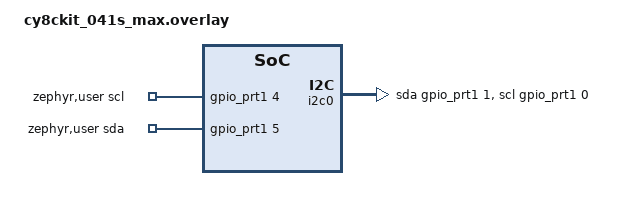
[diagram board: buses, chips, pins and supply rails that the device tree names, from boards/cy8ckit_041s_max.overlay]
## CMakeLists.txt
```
# SPDX-FileCopyrightText: Copyright (c) 2026 Infineon Technologies AG,
# SPDX-FileCopyrightText: or an affiliate of Infineon Technologies AG. All rights reserved.
#
# SPDX-License-Identifier: Apache-2.0

cmake_minimum_required(VERSION 3.28.0)

find_package(Zephyr REQUIRED HINTS $ENV{ZEPHYR_BASE})
project(i2c_fault_injection)

target_sources(app PRIVATE
  src/bus_force.c
  src/i2c_timing.c
  src/main.c
  src/test_addr.c
  src/test_api_misuse.c
  src/test_recovery.c
)
```

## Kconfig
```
# SPDX-FileCopyrightText: Copyright (c) 2026 Infineon Technologies AG,
# SPDX-FileCopyrightText: or an affiliate of Infineon Technologies AG. All rights reserved.
#
# SPDX-License-Identifier: Apache-2.0

mainmenu "I2C fault injection test"

config I2C_FAULT_TEST_ABSENT_ADDR
	hex "7-bit address that nothing on the bus answers"
	default 0x01
	range 0x01 0x77
	help
	  Address that the address-phase tests send to.  The default, 0x01,
	  is the CBUS address.  The I2C-bus specification does not allow
	  I2C-bus compatible devices to respond to it, though a system may
	  assign it to a target when CBUS is not used (UM10204 Rev. 7.0,
	  Table 4 and section 3.1.12).

	  The suite checks with one zero-length write that the address does
	  not answer before using it.  If it answers, every test skips and
	  the log names the address.  Set another address where a device on
	  the bus uses 0x01.

	  This is not a devicetree property, because devicetree describes
	  what is present on a bus and this is an address where nothing is.

config I2C_FAULT_TEST_PRESENT_ADDR
	hex "7-bit address used for the known-good transfers"
	default 0x00
	range 0x00 0x77
	help
	  Address that the suite sends to when it needs to show that the bus
	  still works.  The default, 0x00, means the first enabled devicetree
	  child of the controller under test that answers a zero-length
	  write.  Set a value where the device that answers is not in
	  devicetree.

	  Only the zero-length write is sent to this address, so the device
	  there is not written to.  If nothing answers, the tests that need a
	  known-good address skip.

config I2C_FAULT_TEST_ABSENT_ADDR_10BIT
	hex "10-bit address that nothing on the bus answers"
	default 0x2AA
	range 0x000 0x3FF
	help
	  10-bit address used by the 10-bit addressing test.  The test checks
	  with one zero-length 10-bit write that the address does not answer
	  before sending data, and skips if it does.  Set another address
	  where a device on the bus uses it.

config I2C_FAULT_TEST_BUS_FAULT_WIRED
	bool "The line-forcing GPIOs are wired to the bus"
	help
	  Declares that the GPIOs named by sda-gpios and scl-gpios under the
	  zephyr,user node are wired to the SDA and SCL nets of the controller
	  under test.  The twister scenario with the i2c_bus_fault fixture
	  sets it.

	  Devicetree names the pins but cannot say that a jumper is fitted.
	  Holding lines through pins that are not wired produces failures
	  that look like driver defects, so without this option the tests
	  that hold a line skip.  With it, the build fails unless both
	  properties are present, and setup fails unless both GPIOs are
	  ready.

config I2C_FAULT_TEST_RELAXED_ERRNO
	bool "Accept any negative errno from a failed transfer or recovery"
	help
	  The I2C API documents -EIO for a failed transfer and -ETIMEDOUT for
	  one that reached the transfer timeout, and -EBUSY for a bus that is
	  not clear after a recovery attempt, so by default this suite
	  accepts only those.  Enable this to accept any negative value
	  instead, which is useful when bringing up a driver that is not yet
	  conformant.  In both modes each test logs the value the driver
	  returned.

config I2C_FAULT_TEST_UNSAFE_API_MISUSE
	bool "Run the NULL-buffer condition without userspace"
	help
	  Runs test_misuse_null_buffer, which passes a NULL buffer with a
	  non-zero length, in a build without CONFIG_USERSPACE.  Without
	  userspace, nothing validates the buffer before the driver receives
	  it.  The driver may dereference the NULL pointer or pass it to a DMA
	  engine, and either can fault the CPU and end the run.  Off by
	  default for that reason.

config I2C_FAULT_TEST_TIMEOUT_MS
	int "Time in milliseconds the test waits for a faulted transfer"
	default 2000
	range 100 30000
	help
	  The test wait limit: how long the test thread waits for a faulted
	  transfer, which runs on a worker thread.  A transfer still running
	  at the limit fails the condition where the driver has a transfer
	  timeout shorter than this limit, and skips it elsewhere.  Without
	  the limit, a driver that never returns would show up only as a
	  twister timeout, which looks the same as a build or flash problem.

config I2C_FAULT_TEST_WORKER_STACK_SIZE
	int "Stack size in bytes for the faulted-transfer worker thread"
	default 2048
	range 512 8192
	help
	  Stack for the thread that faulted transfers run on.  It calls
	  nothing deeper than the I2C driver.

config I2C_FAULT_TEST_PAYLOAD_LEN
	int "Bytes transferred by the multi-byte conditions"
	default 8
	range 4 64
	help
	  Length of the data in the multi-byte transfers: the write, read and
	  write-read to the absent address, the read in the alternating-NACK
	  test, and the NULL-buffer write.  A refused transfer then leaves the
	  driver more than one queued byte to discard.

config I2C_FAULT_TEST_REPEAT_COUNT
	int "Attempts made by the repeated-fault conditions"
	default 5
	range 2 100
	help
	  Number of times a fault is repeated when checking that a driver
	  does not latch state from the first failure, and the number of
	  consecutive recovery calls in the repeated-recovery test.

config I2C_FAULT_TEST_HOLD_MS
	int "Milliseconds a line is held low before a recovery"
	default 20
	range 1 1000
	help
	  How long the recovery-after-release test holds SDA low through a
	  forcing GPIO before releasing it and calling i2c_recover_bus().
	  The bus is open drain, so the hold needs no timing precision.

source "Kconfig.zephyr"
```

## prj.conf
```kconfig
# SPDX-FileCopyrightText: Copyright (c) 2026 Infineon Technologies AG,
# SPDX-FileCopyrightText: or an affiliate of Infineon Technologies AG. All rights reserved.
#
# SPDX-License-Identifier: Apache-2.0

CONFIG_ZTEST=y
CONFIG_ZTEST_FATAL_HOOK=y
CONFIG_I2C=y
CONFIG_I2C_TARGET=y
CONFIG_LOG=y
CONFIG_I2C_LOG_LEVEL_WRN=y
```

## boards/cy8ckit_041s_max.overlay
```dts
/*
 * SPDX-FileCopyrightText: Copyright (c) 2026 Infineon Technologies AG,
 * SPDX-FileCopyrightText: or an affiliate of Infineon Technologies AG. All rights reserved.
 *
 * SPDX-License-Identifier: Apache-2.0
 */

/*
 * CY8CKIT-041S-MAX for the I2C fault injection suite.
 *
 * Controller under test: SCB0 on P1[0] SCL and P1[1] SDA, the Arduino I2C
 * pins.  Built with SHIELD=cy15framkit_001 and the shield fitted, its
 * FM24W256 is the known-good device.
 *
 * i2c_bus_fault fixture (kit guide 002-32436 Rev. *D, Table 1):
 *   - J2.6 (P1[4]) to J3.10 (SCL)
 *   - J2.8 (P1[5]) to J3.9 (SDA)
 */

#include <zephyr/dt-bindings/gpio/gpio.h>

/ {
	aliases {
		i2c-dut = &i2c0;
	};

	zephyr,user {
		scl-gpios = <&gpio_prt1 4 GPIO_ACTIVE_HIGH>;
		sda-gpios = <&gpio_prt1 5 GPIO_ACTIVE_HIGH>;
	};
};

/* Enables CONFIG_I2C_INFINEON_BUS_RECOVERY for the recovery tests. */
&i2c0 {
	scl-gpios = <&gpio_prt1 0 GPIO_OPEN_DRAIN>;
	sda-gpios = <&gpio_prt1 1 GPIO_OPEN_DRAIN>;
};
```

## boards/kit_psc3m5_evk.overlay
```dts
/*
 * SPDX-FileCopyrightText: Copyright (c) 2026 Infineon Technologies AG,
 * SPDX-FileCopyrightText: or an affiliate of Infineon Technologies AG. All rights reserved.
 *
 * SPDX-License-Identifier: Apache-2.0
 */

/*
 * KIT_PSC3M5_EVK for the I2C fault injection suite.  The controller under test
 * is SCB0 (i2c0) on P9[0] SCL and P9[2] SDA, at J3.10 and J3.9 (kit user
 * guide 002-39385 Rev. *B, Table 3).  The kit pulls both lines up to VTARG_REF
 * through 4.7 kOhm (R50, R51), so the bus needs no shield for its pull-ups.
 *
 * i2c_bus_fault fixture:
 *   - J5.25 (P9[1]) to J5.21 (SCL)
 *   - J5.11 (P9[4]) to J5.23 (SDA)
 *
 * P9[4] is also routed to the Shield2Go headers (J6.5, J18.5), so fit no
 * Shield2Go board while it is wired.
 */

#include <zephyr/dt-bindings/gpio/gpio.h>

/ {
	aliases {
		i2c-dut = &i2c0;
	};

	zephyr,user {
		scl-gpios = <&gpio_prt9 1 GPIO_ACTIVE_HIGH>;
		sda-gpios = <&gpio_prt9 4 GPIO_ACTIVE_HIGH>;
	};
};

/* Enables CONFIG_I2C_INFINEON_BUS_RECOVERY for the recovery tests. */
&i2c0 {
	scl-gpios = <&gpio_prt9 0 GPIO_OPEN_DRAIN>;
	sda-gpios = <&gpio_prt9 2 GPIO_OPEN_DRAIN>;
};
```

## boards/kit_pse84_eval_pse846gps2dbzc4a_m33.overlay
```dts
/*
 * SPDX-FileCopyrightText: Copyright (c) 2026 Infineon Technologies AG,
 * SPDX-FileCopyrightText: or an affiliate of Infineon Technologies AG. All rights reserved.
 *
 * SPDX-License-Identifier: Apache-2.0
 */

/*
 * KIT_PSE84_EVAL for the I2C fault injection suite (pins from kit user guide
 * 002-39007 Rev. *B, Table 2).
 *
 * Controller under test: i2c0 on P8[0] SCL and P8[1] SDA.
 *
 * i2c_bus_fault fixture, either of:
 *   - J3.5 (P16[2]) to J3.10 (SCL), and J3.3 (P16[3]) to J3.9 (SDA)
 *   - J9.5 (P16[2]) to J17.5 (SCL), and J9.3 (P16[3]) to J17.6 (SDA)
 *
 * P16[2] and P16[3] are also the Arduino SPI MISO and CS pins, so fit no SPI
 * shield while they are wired.  The board's BMI270 answers on i2c0, so use
 * bus_fault here rather than bus_fault.shield.cy15framkit_001.
 */

#include <zephyr/dt-bindings/gpio/gpio.h>

/ {
	aliases {
		i2c-dut = &i2c0;
	};

	zephyr,user {
		scl-gpios = <&gpio_prt16 2 GPIO_ACTIVE_HIGH>;
		sda-gpios = <&gpio_prt16 3 GPIO_ACTIVE_HIGH>;
	};
};

/* Enables CONFIG_I2C_INFINEON_BUS_RECOVERY for the recovery tests. */
&i2c0 {
	scl-gpios = <&gpio_prt8 0 GPIO_OPEN_DRAIN>;
	sda-gpios = <&gpio_prt8 1 GPIO_OPEN_DRAIN>;
};
```

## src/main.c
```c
/*
 * SPDX-FileCopyrightText: Copyright (c) 2026 Infineon Technologies AG,
 * SPDX-FileCopyrightText: or an affiliate of Infineon Technologies AG. All rights reserved.
 *
 * SPDX-License-Identifier: Apache-2.0
 */

/*
 * I2C fault injection suite: setup, address selection and the transfer
 * helpers that run on the worker thread.
 */

#include <errno.h>
#include <string.h>

#include <zephyr/kernel.h>
#include <zephyr/ztest.h>

#include "bus_force.h"
#include "i2c_fault.h"
#include "i2c_timing.h"

static struct i2c_fault_ctx ctx;

const struct i2c_fault_ctx *i2c_fault_ctx(void)
{
	return &ctx;
} /* i2c_fault_ctx() */

void i2c_fault_skip_unbounded(void)
{
	TC_PRINT("\n  the API documents a bounded return only for a driver "
		 "selecting I2C_TRANSFER_TIMEOUT_SUPPORTED with a non-zero "
		 "timeout below CONFIG_I2C_FAULT_TEST_TIMEOUT_MS, so this "
		 "condition skips\n");
	ztest_test_skip();
} /* i2c_fault_skip_unbounded() */

int i2c_fault_xfer_job(void *arg)
{
	const struct i2c_fault_xfer *xfer = arg;

	return i2c_transfer(xfer->bus, xfer->msgs, xfer->num_msgs, xfer->addr);
} /* i2c_fault_xfer_job() */

/*
 * Storage for the transfer given to the worker thread.
 *
 * A job still running at the test wait limit
 * (CONFIG_I2C_FAULT_TEST_TIMEOUT_MS) is left running, so anything the
 * controller may still touch has to outlive the test thread's stack frame.
 * The message array is copied here; the buffers the messages point at are the
 * caller's responsibility and have static storage throughout the suite.
 */
static struct i2c_msg pinned_msgs[I2C_FAULT_MAX_MSGS];
static struct i2c_fault_xfer pinned_xfer;

/*
 * Copy the caller's message array into static storage and point pinned_xfer
 * at it, so a hung transfer on the worker never reads descriptors from a
 * stack frame that has already returned.  Call it only while no job is
 * stuck; otherwise it overwrites the descriptors the stuck job is using.
 */
static void pin_transfer(const struct i2c_fault_xfer *xfer)
{
	zassert_true(xfer->num_msgs <= ARRAY_SIZE(pinned_msgs),
		     "a transfer of %u messages exceeds I2C_FAULT_MAX_MSGS", xfer->num_msgs);

	(void)memcpy(pinned_msgs, xfer->msgs, (size_t)xfer->num_msgs * sizeof(pinned_msgs[0]));

	pinned_xfer.bus = xfer->bus;
	pinned_xfer.addr = xfer->addr;
	pinned_xfer.msgs = pinned_msgs;
	pinned_xfer.num_msgs = xfer->num_msgs;
} /* pin_transfer() */

void i2c_fault_transfer_bounded(const struct i2c_fault_xfer *xfer, const char *condition,
				struct i2c_fault_outcome *out)
{
	pin_transfer(xfer);
	i2c_timing_run_or_fail(i2c_fault_xfer_job, &pinned_xfer, condition, out);
} /* i2c_fault_transfer_bounded() */

/*
 * Send a zero-length write to addr on the worker thread and return the
 * outcome for the caller to check.  A probe that does not return then cannot
 * stall the test thread.
 */
static int probe_bounded(uint16_t addr, struct i2c_fault_outcome *out)
{
	static uint8_t pinned_scratch;
	struct i2c_msg msg;
	struct i2c_fault_xfer xfer;

	msg.buf = &pinned_scratch;
	msg.len = 0U;
	msg.flags = I2C_MSG_WRITE | I2C_MSG_STOP;

	xfer.bus = ctx.dut;
	xfer.addr = addr;
	xfer.msgs = &msg;
	xfer.num_msgs = 1U;

	pin_transfer(&xfer);

	return i2c_timing_run_bounded(i2c_fault_xfer_job, &pinned_xfer, out);
} /* probe_bounded() */

/*
 * Byte-mode callbacks for i2c_fault_noop_callbacks.  Each returns 0, and the
 * read callbacks supply 0xFF.
 */
static int noop_write_requested(struct i2c_target_config *config)
{
	ARG_UNUSED(config);

	return 0;
} /* noop_write_requested() */

static int noop_write_received(struct i2c_target_config *config, uint8_t val)
{
	ARG_UNUSED(config);
	ARG_UNUSED(val);

	return 0;
} /* noop_write_received() */

static int noop_read_requested(struct i2c_target_config *config, uint8_t *val)
{
	ARG_UNUSED(config);

	*val = 0xFFU;

	return 0;
} /* noop_read_requested() */

static int noop_read_processed(struct i2c_target_config *config, uint8_t *val)
{
	ARG_UNUSED(config);

	*val = 0xFFU;

	return 0;
} /* noop_read_processed() */

static int noop_stop(struct i2c_target_config *config)
{
	ARG_UNUSED(config);

	return 0;
} /* noop_stop() */

const struct i2c_target_callbacks i2c_fault_noop_callbacks = {
	.write_requested = noop_write_requested,
	.read_requested = noop_read_requested,
	.write_received = noop_write_received,
	.read_processed = noop_read_processed,
	.stop = noop_stop,
};

void i2c_fault_record(const char *condition, int ret)
{
	TC_PRINT("  %s: driver returned %d\n", condition, ret);
} /* i2c_fault_record() */

void i2c_fault_assert_error(int ret, const char *condition)
{
	i2c_fault_record(condition, ret);

	if (IS_ENABLED(CONFIG_I2C_FAULT_TEST_RELAXED_ERRNO)) {
		zassert_true(ret < 0, "%s: expected a negative errno, got %d", condition, ret);
	} else {
		/*
		 * The I2C API documents -EIO for a failed transfer, and the I2C
		 * documentation's "Transfer Timeout" section documents
		 * -ETIMEDOUT for one that ran out of time.
		 */
		zassert_true((ret == -EIO) || (ret == -ETIMEDOUT),
			     "%s: the I2C API documents -EIO for a failed "
			     "transfer and -ETIMEDOUT for one that timed out, "
			     "got %d",
			     condition, ret);
	}
} /* i2c_fault_assert_error() */

void i2c_fault_assert_healthy(const char *condition)
{
	struct i2c_fault_outcome outcome;
	uint16_t addr = ctx.have_present ? ctx.present_addr : ctx.absent_addr;

	/*
	 * A driver that kept its bus lock after the fault would stall the run
	 * here, so this probe runs on the worker thread like a faulted transfer.
	 */
	(void)probe_bounded(addr, &outcome);
	I2C_FAULT_ASSERT_RETURNED(&outcome,
				  "%s: a probe of 0x%02x did not return within "
				  "%d ms after the fault",
				  condition, addr, CONFIG_I2C_FAULT_TEST_TIMEOUT_MS);

	if (ctx.have_present) {
		zassert_ok(outcome.ret,
			   "%s: the bus was left unusable, address 0x%02x "
			   "stopped answering (%d)",
			   condition, addr, outcome.ret);
		return;
	}

	/*
	 * With nothing on the bus to answer, the weaker check is that a
	 * transfer to the absent address still fails, rather than answering
	 * or hanging.
	 */
	zassert_true(outcome.ret < 0,
		     "%s: absent address 0x%02x began answering after the "
		     "fault (%d)",
		     condition, addr, outcome.ret);
} /* i2c_fault_assert_healthy() */

void i2c_fault_require_present(void)
{
	if (!ctx.have_present) {
		TC_PRINT("  no known-good address answered at setup\n");
		ztest_test_skip();
	}
} /* i2c_fault_require_present() */

void i2c_fault_require_bus_force(void)
{
	if (!ctx.bus_force_ready) {
		TC_PRINT("  line forcing not wired; the i2c_bus_fault fixture and sda-gpios and "
			 "scl-gpios under zephyr,user are required\n");
		ztest_test_skip();
	}
} /* i2c_fault_require_bus_force() */

/*
 * Configure the forcing GPIOs, released, and check that both lines read high.
 * An idle bus is pulled high, so a low line before any test has run means the
 * bus is already stuck or a forcing jumper is on the wrong net, and every
 * result after it would mislead.
 */
static void setup_bus_force(void)
{
	uint32_t level;
	int ret;

	ret = bus_force_init();
	zassert_ok(ret, "could not configure the line-forcing GPIOs (%d)", ret);

	ctx.bus_force_ready = IS_ENABLED(CONFIG_I2C_FAULT_TEST_BUS_FAULT_WIRED);
	if (!ctx.bus_force_ready) {
		return;
	}

	ret = bus_force_level(BUS_FORCE_SDA | BUS_FORCE_SCL);
	zassert_true(ret >= 0, "could not read the bus lines (%d)", ret);
	level = (uint32_t)ret;
	zassert_equal(level, BUS_FORCE_SDA | BUS_FORCE_SCL,
		      "SDA reads %s and SCL reads %s; check the i2c_bus_fault wiring",
		      ((level & BUS_FORCE_SDA) != 0U) ? "high" : "low",
		      ((level & BUS_FORCE_SCL) != 0U) ? "high" : "low");
} /* setup_bus_force() */

/* Devicetree address of one enabled child of the controller under test. */
#define DUT_CHILD_ADDR(node_id) (uint16_t)DT_REG_ADDR(node_id),

/*
 * Probe addr on the worker thread during setup.  A probe that does not return
 * within the wait limit marks the bus unusable, so every test skips.
 */
static bool setup_probe(uint16_t addr, struct i2c_fault_outcome *outcome)
{
	(void)probe_bounded(addr, outcome);

	if (outcome->timed_out) {
		TC_PRINT("  a setup probe of 0x%02x did not return within %d ms\n", addr,
			 CONFIG_I2C_FAULT_TEST_TIMEOUT_MS);
		ctx.bus_unusable = true;
		return false;
	}

	return true;
} /* setup_probe() */

/*
 * Settle on the two addresses the suite works with, each verified by one
 * zero-length write before it is trusted.
 *
 * The absent address is CONFIG_I2C_FAULT_TEST_ABSENT_ADDR, by default 0x01,
 * the CBUS address, which I2C-bus compatible devices are not allowed to
 * respond to, though a system may assign it to a target when CBUS is not
 * used (UM10204 Rev. 7.0, Table 4 and section 3.1.12).  The known-good
 * address is CONFIG_I2C_FAULT_TEST_PRESENT_ADDR where set, and otherwise the
 * first enabled devicetree child of the controller that answers.  No other
 * address is probed.
 */
static void select_addresses(void)
{
	/* The trailing 0 keeps the array non-empty on a controller with no children. */
	static const uint16_t dt_addrs[] = {
		DT_FOREACH_CHILD_STATUS_OKAY(I2C_FAULT_DUT_NODE, DUT_CHILD_ADDR) 0U};
	struct i2c_fault_outcome outcome;

	ctx.absent_addr = (uint16_t)CONFIG_I2C_FAULT_TEST_ABSENT_ADDR;

	if (!setup_probe(ctx.absent_addr, &outcome)) {
		return;
	}

	/*
	 * Every test reads a refused zero-length write as an absent address.
	 * The API does not require a driver to support that probe, so a
	 * controller on which the absent address does not refuse it skips the
	 * run instead of failing it.  -ETIMEDOUT is not a refusal: the probe
	 * never completed, so it says nothing about the address.
	 */
	if ((outcome.ret >= 0) || (outcome.ret == -ETIMEDOUT)) {
		TC_PRINT("  absent address 0x%02x did not refuse a zero-length write (%d); "
			 "set CONFIG_I2C_FAULT_TEST_ABSENT_ADDR to an address nothing answers\n",
			 ctx.absent_addr, outcome.ret);
		ctx.probe_unusable = true;
		return;
	}

	if (CONFIG_I2C_FAULT_TEST_PRESENT_ADDR != 0) {
		if (setup_probe((uint16_t)CONFIG_I2C_FAULT_TEST_PRESENT_ADDR, &outcome) &&
		    (outcome.ret == 0)) {
			ctx.present_addr = (uint16_t)CONFIG_I2C_FAULT_TEST_PRESENT_ADDR;
			ctx.have_present = true;
		}
		return;
	}

	for (size_t i = 0U; (i < (ARRAY_SIZE(dt_addrs) - 1U)) && !ctx.have_present; i++) {
		/* A 10-bit child cannot be checked with a 7-bit probe. */
		if (dt_addrs[i] > 0x7FU) {
			continue;
		}

		if (!setup_probe(dt_addrs[i], &outcome)) {
			return;
		}

		if (outcome.ret == 0) {
			ctx.present_addr = dt_addrs[i];
			ctx.have_present = true;
		}
	}
} /* select_addresses() */

/* Report the addresses setup settled on, so a skipped test is explicable. */
static void report_environment(void)
{
	TC_PRINT("I2C fault injection environment\n");
	TC_PRINT("  controller under test: %s\n", ctx.dut->name);
	TC_PRINT("  absent address:        0x%02x\n", ctx.absent_addr);

	if (ctx.have_present) {
		TC_PRINT("  known-good address:    0x%02x\n", ctx.present_addr);
	} else {
		TC_PRINT("  known-good address:    none found\n");
	}

	TC_PRINT("  line forcing:          %s\n", ctx.bus_force_ready ? "available" : "not wired");
} /* report_environment() */

void *i2c_fault_setup(void)
{
	static bool ctx_valid;

	/*
	 * Each ztest suite calls this hook.  Only the first call sets up ctx,
	 * so every suite works with the same controller and addresses and the
	 * addresses are probed once.
	 */
	if (ctx_valid) {
		return NULL;
	}

	ctx.dut = DEVICE_DT_GET(I2C_FAULT_DUT_NODE);
	zassert_true(device_is_ready(ctx.dut), "controller under test is not ready");

	i2c_timing_harness_start();

	setup_bus_force();
	select_addresses();
	report_environment();

	ctx_valid = true;

	return NULL;
} /* i2c_fault_setup() */

void i2c_fault_before(void *fixture)
{
	ARG_UNUSED(fixture);

	/*
	 * A transfer that did not return within the wait limit may only have
	 * been slow.  Waiting for it once lets the run continue after a slow
	 * driver; one that still has not returned is treated as hung for the
	 * rest of the run.
	 */
	if (!ctx.hang_detected && i2c_timing_harness_stuck() && !i2c_timing_harness_recover()) {
		ctx.hang_detected = true;
	}

	if (ctx.hang_detected) {
		TC_PRINT("  an earlier transfer had still not returned %d ms "
			 "after the wait limit, so the bus state is unknown\n",
			 CONFIG_I2C_FAULT_TEST_TIMEOUT_MS);
		ztest_test_skip();
		return;
	}

	if (ctx.bus_unusable) {
		TC_PRINT("  a setup probe did not return within %d ms, so no address could be "
			 "verified\n",
			 CONFIG_I2C_FAULT_TEST_TIMEOUT_MS);
		ztest_test_skip();
		return;
	}

	if (ctx.probe_unusable) {
		TC_PRINT("  the absent address did not refuse a zero-length write, so no test "
			 "can run\n");
		ztest_test_skip();
		return;
	}
} /* i2c_fault_before() */

ZTEST_SUITE(i2c_fault_harness, NULL, i2c_fault_setup, i2c_fault_before, NULL, NULL);

/**
 * @brief The environment the rest of the suite depends on.
 *
 * @details
 * Test that the controller under test is ready and that the absent address
 * chosen at setup still refuses a zero-length write, sent on the worker
 * thread.  Every address-phase test depends on both, so this should pass
 * whenever the rest of the suite runs.  Catches a setup path that leaves the
 * suite running against a controller that is not ready, or against an
 * address that answers.
 *
 * Requires: one I2C controller.  No fixture.
 */
ZTEST(i2c_fault_harness, test_environment)
{
	struct i2c_fault_outcome outcome;

	zassert_true(device_is_ready(ctx.dut), "controller under test is not ready");

	(void)probe_bounded(ctx.absent_addr, &outcome);
	I2C_FAULT_ASSERT_RETURNED(&outcome,
				  "a probe of the absent address 0x%02x did not return "
				  "within %d ms",
				  ctx.absent_addr, CONFIG_I2C_FAULT_TEST_TIMEOUT_MS);
	zassert_true(outcome.ret < 0, "absent address 0x%02x answers", ctx.absent_addr);
} /* test_environment() */
```

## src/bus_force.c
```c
/*
 * SPDX-FileCopyrightText: Copyright (c) 2026 Infineon Technologies AG,
 * SPDX-FileCopyrightText: or an affiliate of Infineon Technologies AG. All rights reserved.
 *
 * SPDX-License-Identifier: Apache-2.0
 */

#include <errno.h>

#include <zephyr/devicetree.h>
#include <zephyr/drivers/gpio.h>
#include <zephyr/kernel.h>

#include "bus_force.h"

#define ZEPHYR_USER_NODE DT_PATH(zephyr_user)

static const struct gpio_dt_spec sda = GPIO_DT_SPEC_GET_OR(ZEPHYR_USER_NODE, sda_gpios, {0});
static const struct gpio_dt_spec scl = GPIO_DT_SPEC_GET_OR(ZEPHYR_USER_NODE, scl_gpios, {0});

BUILD_ASSERT(!IS_ENABLED(CONFIG_I2C_FAULT_TEST_BUS_FAULT_WIRED) ||
		     (DT_NODE_HAS_PROP(ZEPHYR_USER_NODE, sda_gpios) &&
		      DT_NODE_HAS_PROP(ZEPHYR_USER_NODE, scl_gpios)),
	     "CONFIG_I2C_FAULT_TEST_BUS_FAULT_WIRED needs zephyr,user sda-gpios and scl-gpios");

/*
 * A pin is an output only while it holds a line low, so the forcing GPIOs
 * leave the bus alone at rest and a test that aborts cannot leave it held.
 */
int bus_force_init(void)
{
	int ret;

	if (!IS_ENABLED(CONFIG_I2C_FAULT_TEST_BUS_FAULT_WIRED)) {
		return 0;
	}

	if (!gpio_is_ready_dt(&sda) || !gpio_is_ready_dt(&scl)) {
		return -ENODEV;
	}

	ret = gpio_pin_configure_dt(&sda, GPIO_INPUT);
	if (ret < 0) {
		return ret;
	}

	return gpio_pin_configure_dt(&scl, GPIO_INPUT);
} /* bus_force_init() */

int bus_force_low(uint32_t lines)
{
	int ret;

	if (!IS_ENABLED(CONFIG_I2C_FAULT_TEST_BUS_FAULT_WIRED)) {
		return -ENODEV;
	}

	if ((lines == 0U) || ((lines & ~(BUS_FORCE_SDA | BUS_FORCE_SCL)) != 0U)) {
		return -EINVAL;
	}

	if ((lines & BUS_FORCE_SDA) != 0U) {
		ret = gpio_pin_configure_dt(&sda, GPIO_OUTPUT_INACTIVE);
		if (ret < 0) {
			return ret;
		}
	}

	if ((lines & BUS_FORCE_SCL) != 0U) {
		ret = gpio_pin_configure_dt(&scl, GPIO_OUTPUT_INACTIVE);
		if (ret < 0) {
			return ret;
		}
	}

	return 0;
} /* bus_force_low() */

int bus_force_release(void)
{
	int ret;

	if (!IS_ENABLED(CONFIG_I2C_FAULT_TEST_BUS_FAULT_WIRED)) {
		return -ENODEV;
	}

	ret = gpio_pin_configure_dt(&sda, GPIO_INPUT);
	if (ret < 0) {
		return ret;
	}

	return gpio_pin_configure_dt(&scl, GPIO_INPUT);
} /* bus_force_release() */

/* Read @p pin as an input, and add @p bit to @p high when the line is high. */
static int read_line(const struct gpio_dt_spec *pin, uint32_t bit, uint32_t *high)
{
	int ret;

	/* A pin driving the line low would read back its own drive, not the bus. */
	ret = gpio_pin_configure_dt(pin, GPIO_INPUT);
	if (ret < 0) {
		return ret;
	}

	ret = gpio_pin_get_dt(pin);
	if (ret < 0) {
		return ret;
	}

	if (ret == 1) {
		*high |= bit;
	}

	return 0;
} /* read_line() */

int bus_force_level(uint32_t lines)
{
	uint32_t high = 0U;
	int ret;

	if (!IS_ENABLED(CONFIG_I2C_FAULT_TEST_BUS_FAULT_WIRED)) {
		return -ENODEV;
	}

	if ((lines == 0U) || ((lines & ~(BUS_FORCE_SDA | BUS_FORCE_SCL)) != 0U)) {
		return -EINVAL;
	}

	if ((lines & BUS_FORCE_SDA) != 0U) {
		ret = read_line(&sda, BUS_FORCE_SDA, &high);
		if (ret < 0) {
			return ret;
		}
	}

	if ((lines & BUS_FORCE_SCL) != 0U) {
		ret = read_line(&scl, BUS_FORCE_SCL, &high);
		if (ret < 0) {
			return ret;
		}
	}

	return (int)high;
} /* bus_force_level() */
```

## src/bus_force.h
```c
/*
 * SPDX-FileCopyrightText: Copyright (c) 2026 Infineon Technologies AG,
 * SPDX-FileCopyrightText: or an affiliate of Infineon Technologies AG. All rights reserved.
 *
 * SPDX-License-Identifier: Apache-2.0
 */

/*
 * Holding SDA or SCL low through spare GPIOs wired to the bus.
 *
 * The bus is open drain, so a pin driving a line low holds it low whatever
 * the controller under test drives.  A hold lasts milliseconds and needs no
 * timing precision.
 *
 * The pins are sda-gpios and scl-gpios under the zephyr,user node.  They must
 * be spare GPIOs wired to the controller's own SDA and SCL nets, declared
 * GPIO_ACTIVE_HIGH so that a logical 0 is a physical low.
 */

#ifndef BUS_FORCE_H_
#define BUS_FORCE_H_

#include <stdint.h>

#include <zephyr/sys/util_macro.h>

/** Bus lines that can be held low, combined with a bitwise OR. */
#define BUS_FORCE_SDA BIT(0)
#define BUS_FORCE_SCL BIT(1)

/**
 * Configure both forcing GPIOs as inputs, leaving the lines released.
 *
 * Does nothing unless CONFIG_I2C_FAULT_TEST_BUS_FAULT_WIRED is set.
 *
 * @retval 0        Success, or the option is not set.
 * @retval -ENODEV  A forcing GPIO's controller is not ready.
 * @retval -errno   Error from the GPIO driver.
 */
int bus_force_init(void);

/**
 * Hold @p lines low until bus_force_release() is called.
 *
 * @param lines BUS_FORCE_SDA, BUS_FORCE_SCL, or both.
 *
 * @retval 0        Success.
 * @retval -EINVAL  @p lines is 0 or has a bit set that names no line.
 * @retval -ENODEV  CONFIG_I2C_FAULT_TEST_BUS_FAULT_WIRED is not set.
 * @retval -errno   Error from the GPIO driver.
 */
int bus_force_low(uint32_t lines);

/**
 * Release both lines.
 *
 * @retval 0        Success.
 * @retval -ENODEV  CONFIG_I2C_FAULT_TEST_BUS_FAULT_WIRED is not set.
 * @retval -errno   Error from the GPIO driver.
 */
int bus_force_release(void);

/**
 * Read the level of one or both lines.
 *
 * Each pin read is switched to an input first, so a line this helper holds
 * low is released by the read.
 *
 * @param lines BUS_FORCE_SDA, BUS_FORCE_SCL, or both.
 *
 * @retval >=0      The lines in @p lines that read high.
 * @retval -EINVAL  @p lines is 0 or has a bit set that names no line.
 * @retval -ENODEV  CONFIG_I2C_FAULT_TEST_BUS_FAULT_WIRED is not set.
 * @retval -errno   Error from the GPIO driver.
 */
int bus_force_level(uint32_t lines);

#endif /* BUS_FORCE_H_ */
```

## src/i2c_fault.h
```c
/*
 * SPDX-FileCopyrightText: Copyright (c) 2026 Infineon Technologies AG,
 * SPDX-FileCopyrightText: or an affiliate of Infineon Technologies AG. All rights reserved.
 *
 * SPDX-License-Identifier: Apache-2.0
 */

/*
 * Shared state and helpers for the I2C fault injection suite.
 *
 * Each test file covers one fault class and needs the controller under test,
 * an address that nothing on the bus answers, and a way to assert that a
 * faulted transfer failed rather than hung.  The test setup is done in
 * main.c, and the test files reach its results through i2c_fault_ctx() and
 * the helpers declared here.
 */

#ifndef I2C_FAULT_H_
#define I2C_FAULT_H_

#include <stdbool.h>
#include <stdint.h>

#include <zephyr/device.h>
#include <zephyr/devicetree.h>
#include <zephyr/drivers/i2c.h>
#include <zephyr/ztest.h>

/* Defines struct i2c_fault_outcome, which the transfer helpers below return. */
#include "i2c_timing.h"

/* Controller under test.  Every board supporting the suite provides this. */
#define I2C_FAULT_DUT_NODE DT_ALIAS(i2c_dut)

BUILD_ASSERT(DT_NODE_HAS_STATUS_OKAY(I2C_FAULT_DUT_NODE),
	     "the i2c-dut alias must name an enabled I2C controller");

/*
 * A bounded return is documented only for a driver that selects
 * I2C_TRANSFER_TIMEOUT_SUPPORTED with a non-zero timeout, resolved from
 * zephyr,transfer-timeout-ms or CONFIG_I2C_TRANSFER_TIMEOUT_MS
 * (doc/hardware/peripherals/i2c.rst, "Transfer Timeout").  The suite can hold
 * a driver to it only when that timeout is shorter than the test wait limit
 * (CONFIG_I2C_FAULT_TEST_TIMEOUT_MS).
 */
#if defined(CONFIG_I2C_TRANSFER_TIMEOUT_SUPPORTED)
#define I2C_FAULT_DUT_TIMEOUT_MS                                                                   \
	DT_PROP_OR(I2C_FAULT_DUT_NODE, zephyr_transfer_timeout_ms, CONFIG_I2C_TRANSFER_TIMEOUT_MS)
#define I2C_FAULT_BOUND_DOCUMENTED                                                                 \
	((I2C_FAULT_DUT_TIMEOUT_MS > 0) &&                                                         \
	 (I2C_FAULT_DUT_TIMEOUT_MS < CONFIG_I2C_FAULT_TEST_TIMEOUT_MS))
#else
#define I2C_FAULT_BOUND_DOCUMENTED 0
#endif

/* Payload length the conditions transfer. */
#define I2C_FAULT_PAYLOAD_LEN CONFIG_I2C_FAULT_TEST_PAYLOAD_LEN

/** The controller under test, the addresses setup settled on, and setup results. */
struct i2c_fault_ctx {
	/** Controller under test. */
	const struct device *dut;
	/** Address on the bus under test that nothing answers. */
	uint16_t absent_addr;
	/** Address that answers, used for the known-good transfers. */
	uint16_t present_addr;
	/** Set when the known-good address answered its setup probe. */
	bool have_present;
	/**
	 * Set when a setup probe did not return within the wait limit.  No
	 * address could be verified, so every test skips.
	 */
	bool bus_unusable;
	/**
	 * Set when the absent address did not refuse its setup probe.  Every
	 * test relies on that refusal, and the API does not require a driver
	 * to support a zero-length write, so the run skips rather than fails.
	 */
	bool probe_unusable;
	/** Set once a transfer has failed to return within the wait limit. */
	bool hang_detected;
	/** Set when CONFIG_I2C_FAULT_TEST_BUS_FAULT_WIRED declares the forcing GPIOs wired. */
	bool bus_force_ready;
};

const struct i2c_fault_ctx *i2c_fault_ctx(void);

void *i2c_fault_setup(void);
void i2c_fault_before(void *fixture);

/**
 * Skip the running test after a transfer did not return within the wait limit
 * on a controller for which the API documents no bounded return.
 */
void i2c_fault_skip_unbounded(void);

/**
 * Assert that a transfer run on the worker thread returned within the wait
 * limit.
 *
 * Where I2C_FAULT_BOUND_DOCUMENTED holds, a transfer that did not return
 * within the wait limit fails the test with the given message.  Elsewhere the
 * message is printed and the test skips, because the API does not promise the
 * driver returns.
 */
#define I2C_FAULT_ASSERT_RETURNED(outcome, ...)                                                    \
	do {                                                                                       \
		if ((outcome)->timed_out && !I2C_FAULT_BOUND_DOCUMENTED) {                         \
			TC_PRINT("  " __VA_ARGS__);                                                \
			i2c_fault_skip_unbounded();                                                \
		} else {                                                                           \
			zassert_false((outcome)->timed_out, __VA_ARGS__);                          \
		}                                                                                  \
	} while (false)

/** Skip the running test unless a known-good address is available. */
void i2c_fault_require_present(void);

/** Skip the running test unless the forcing GPIOs are wired and ready. */
void i2c_fault_require_bus_force(void);

/**
 * Assert that @p ret reports a failed transfer.
 *
 * The I2C API documents -EIO for a failed transfer and -ETIMEDOUT for one
 * that reached the transfer timeout, so those are what this requires by
 * default.  CONFIG_I2C_FAULT_TEST_RELAXED_ERRNO weakens it to any negative
 * value for bringing up a driver that is not yet conformant.  Either way the
 * value is recorded, because collecting what drivers return is one of the
 * outputs of this suite.
 */
void i2c_fault_assert_error(int ret, const char *condition);

/** Record the value a driver returned without asserting anything about it. */
void i2c_fault_record(const char *condition, int ret);

/**
 * Assert that the bus still works after a fault: the known-good address
 * still answers or, where none was found, the absent address still refuses.
 */
void i2c_fault_assert_healthy(const char *condition);

/**
 * Byte-mode callback table for a target registered only to check that
 * registration works.
 *
 * The I2C API does not mark any target callback optional, so a controller
 * driver may call these without checking for NULL when the target is
 * addressed.  They accept every write and return 0xFF for every read.
 */
extern const struct i2c_target_callbacks i2c_fault_noop_callbacks;

/**
 * Largest number of messages in one transfer run on the worker thread.  The
 * message array is copied into static storage of this size.
 */
#define I2C_FAULT_MAX_MSGS 4

/**
 * The arguments of one i2c_transfer() call, gathered into one struct so they
 * can be passed to i2c_fault_xfer_job(), which takes a single argument.
 */
struct i2c_fault_xfer {
	const struct device *bus;
	uint16_t addr;
	struct i2c_msg *msgs;
	uint8_t num_msgs;
};

/**
 * Job entry point that performs an @ref i2c_fault_xfer.
 *
 * Faulted transfers run on the worker thread rather than in the test thread,
 * so that a driver which never returns is reported as a hang instead of
 * stalling the whole run.
 */
int i2c_fault_xfer_job(void *arg);

/**
 * Run a transfer on the worker thread and report it through
 * I2C_FAULT_ASSERT_RETURNED() if it does not return within the wait limit.
 *
 * The message array is copied into static storage, because a job still
 * running at the wait limit is left running and the controller may still be
 * reading the descriptors after the test thread has unwound its stack.  The
 * data buffers the messages point at are not copied and must therefore
 * outlive the run; the suite gives them static storage for that reason.
 *
 * @param[in]  xfer      transfer to perform, at most @ref I2C_FAULT_MAX_MSGS
 *                       messages.
 * @param[in]  condition condition identifier used in the failure message.
 * @param[out] out       result and elapsed time.
 */
void i2c_fault_transfer_bounded(const struct i2c_fault_xfer *xfer, const char *condition,
				struct i2c_fault_outcome *out);

#endif /* I2C_FAULT_H_ */
```

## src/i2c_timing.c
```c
/*
 * SPDX-FileCopyrightText: Copyright (c) 2026 Infineon Technologies AG,
 * SPDX-FileCopyrightText: or an affiliate of Infineon Technologies AG. All rights reserved.
 *
 * SPDX-License-Identifier: Apache-2.0
 */

#include <errno.h>

#include <zephyr/kernel.h>
#include <zephyr/ztest.h>

#include "i2c_fault.h"
#include "i2c_timing.h"

static K_THREAD_STACK_DEFINE(worker_stack, CONFIG_I2C_FAULT_TEST_WORKER_STACK_SIZE);
static struct k_thread worker_thread;
static K_SEM_DEFINE(work_ready, 0, 1);
static K_SEM_DEFINE(work_done, 0, 1);

static i2c_fault_job_fn job_fn;
static void *job_arg;
static int job_ret;
static struct i2c_timing_span job_span;
static bool harness_stuck;

void i2c_timing_begin(struct i2c_timing_span *span)
{
	span->start = k_cycle_get_32();
	span->end = span->start;
} /* i2c_timing_begin() */

void i2c_timing_end(struct i2c_timing_span *span)
{
	span->end = k_cycle_get_32();
} /* i2c_timing_end() */

uint32_t i2c_timing_us(const struct i2c_timing_span *span)
{
	uint32_t elapsed = span->end - span->start;

	return (uint32_t)k_cyc_to_us_floor64((uint64_t)elapsed);
} /* i2c_timing_us() */

/*
 * The worker runs one job per work_ready token and never exits, so the thread
 * is created once for the whole suite.  A job that hangs keeps this loop
 * blocked in job_fn(); i2c_timing_run_bounded() reports that state and leaves
 * the thread alone.
 */
static void worker_entry(void *p1, void *p2, void *p3)
{
	ARG_UNUSED(p1);
	ARG_UNUSED(p2);
	ARG_UNUSED(p3);

	while (true) {
		(void)k_sem_take(&work_ready, K_FOREVER);

		i2c_timing_begin(&job_span);
		job_ret = job_fn(job_arg);
		i2c_timing_end(&job_span);

		k_sem_give(&work_done);
	}
} /* worker_entry() */

void i2c_timing_harness_start(void)
{
	static bool harness_started;
	int priority;

	if (harness_started) {
		return;
	}

	/*
	 * The test thread has to take the CPU back from the worker when the
	 * test wait limit (CONFIG_I2C_FAULT_TEST_TIMEOUT_MS) expires, even from
	 * a driver that polls the bus instead of sleeping.  A cooperative thread
	 * cannot be preempted, and the ztest thread is cooperative by default
	 * (CONFIG_ZTEST_THREAD_PRIORITY).
	 *
	 * The worker therefore runs one priority level below the thread that
	 * started it.  If that level is still cooperative, the worker runs at
	 * 0, the highest preemptible priority, instead.
	 */
	priority = k_thread_priority_get(k_current_get()) + 1;
	if (priority < 0) {
		priority = 0;
	}

	(void)k_thread_create(&worker_thread, worker_stack, K_THREAD_STACK_SIZEOF(worker_stack),
			      worker_entry, NULL, NULL, NULL, priority, 0, K_NO_WAIT);
	(void)k_thread_name_set(&worker_thread, "i2c_fault_worker");

	harness_started = true;
} /* i2c_timing_harness_start() */

int i2c_timing_submit(i2c_fault_job_fn fn, void *arg)
{
	/* The worker is still blocked in an earlier job and cannot take this one. */
	if (harness_stuck) {
		return -ETIMEDOUT;
	}

	job_fn = fn;
	job_arg = arg;
	k_sem_give(&work_ready);

	return 0;
} /* i2c_timing_submit() */

int i2c_timing_collect(struct i2c_fault_outcome *out)
{
	uint32_t bound_ms = (uint32_t)CONFIG_I2C_FAULT_TEST_TIMEOUT_MS;

	out->ret = 0;
	out->elapsed_us = 0U;
	out->start_cycles = 0U;
	out->end_cycles = 0U;
	out->timed_out = false;

	/* While stuck, nothing new was submitted; a completion now is the old job's. */
	if (harness_stuck || (k_sem_take(&work_done, K_MSEC(bound_ms)) != 0)) {
		harness_stuck = true;
		out->timed_out = true;
		out->elapsed_us = bound_ms * USEC_PER_MSEC;
		return -ETIMEDOUT;
	}

	out->ret = job_ret;
	out->elapsed_us = i2c_timing_us(&job_span);
	out->start_cycles = job_span.start;
	out->end_cycles = job_span.end;

	return 0;
} /* i2c_timing_collect() */

bool i2c_timing_harness_recover(void)
{
	uint32_t bound_ms = (uint32_t)CONFIG_I2C_FAULT_TEST_TIMEOUT_MS;

	if (!harness_stuck) {
		return true;
	}

	/* Still running after a second wait limit, so the job stays stuck. */
	if (k_sem_take(&work_done, K_MSEC(bound_ms)) != 0) {
		return false;
	}

	/* The late result is dropped; nobody is waiting for it any more. */
	harness_stuck = false;

	return true;
} /* i2c_timing_harness_recover() */

int i2c_timing_run_bounded(i2c_fault_job_fn fn, void *arg, struct i2c_fault_outcome *out)
{
	int ret = i2c_timing_submit(fn, arg);

	/* The job never started, so report it as not returned without waiting. */
	if (ret != 0) {
		out->ret = 0;
		out->elapsed_us = (uint32_t)CONFIG_I2C_FAULT_TEST_TIMEOUT_MS * USEC_PER_MSEC;
		out->start_cycles = 0U;
		out->end_cycles = 0U;
		out->timed_out = true;
		return ret;
	}

	return i2c_timing_collect(out);
} /* i2c_timing_run_bounded() */

bool i2c_timing_harness_stuck(void)
{
	return harness_stuck;
} /* i2c_timing_harness_stuck() */

void i2c_timing_run_or_fail(i2c_fault_job_fn fn, void *arg, const char *condition,
			    struct i2c_fault_outcome *out)
{
	(void)i2c_timing_run_bounded(fn, arg, out);

	I2C_FAULT_ASSERT_RETURNED(out,
				  "%s: transfer did not return within %d ms; "
				  "the driver hung rather than reporting an "
				  "error",
				  condition, CONFIG_I2C_FAULT_TEST_TIMEOUT_MS);
} /* i2c_timing_run_or_fail() */
```

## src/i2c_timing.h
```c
/*
 * SPDX-FileCopyrightText: Copyright (c) 2026 Infineon Technologies AG,
 * SPDX-FileCopyrightText: or an affiliate of Infineon Technologies AG. All rights reserved.
 *
 * SPDX-License-Identifier: Apache-2.0
 */

/*
 * Cycle-counter instrumentation and the worker thread that runs faulted
 * transfers.
 *
 * Timing uses k_cycle_get_32() and sys_clock_hw_cycles_per_sec(), which are
 * available on every platform and need no peripheral.
 *
 * A driver that never returns cannot be detected from the thread that called
 * it, because that thread is the one stuck.  Transfers therefore run on a
 * worker thread, and the test thread waits for each one for at most the test
 * wait limit, CONFIG_I2C_FAULT_TEST_TIMEOUT_MS.
 */

#ifndef I2C_TIMING_H_
#define I2C_TIMING_H_

#include <stdbool.h>
#include <stdint.h>

/** A measured interval, in cycle-counter ticks. */
struct i2c_timing_span {
	uint32_t start;
	uint32_t end;
};

/** Result of running a job on the worker thread. */
struct i2c_fault_outcome {
	/** Value the job returned, meaningless when timed_out is set. */
	int ret;
	/** Microseconds from job start to return, or the wait limit if it timed out. */
	uint32_t elapsed_us;
	/** Cycle counter sampled immediately before the job ran. */
	uint32_t start_cycles;
	/** Cycle counter sampled immediately after the job returned. */
	uint32_t end_cycles;
	/** Set when the job did not return within the wait limit. */
	bool timed_out;
};

/** Signature of a job run on the worker thread. */
typedef int (*i2c_fault_job_fn)(void *arg);

/** Sample the cycle counter at the start of an interval. */
void i2c_timing_begin(struct i2c_timing_span *span);

/** Sample the cycle counter at the end of an interval. */
void i2c_timing_end(struct i2c_timing_span *span);

/** Length of a measured interval in microseconds. */
uint32_t i2c_timing_us(const struct i2c_timing_span *span);

/**
 * Start the worker thread that runs jobs.
 *
 * Called once from the suite setup.  Safe to call again; later calls do
 * nothing.
 */
void i2c_timing_harness_start(void);

/**
 * Run @p fn on the worker thread and give it up to the wait limit to return.
 *
 * A job still running at the wait limit is left running.  Aborting the worker
 * in the middle of a driver call would leave the controller in an unknown
 * state.
 *
 * @param[in]  fn  job to run.
 * @param[in]  arg passed to @p fn unchanged.
 * @param[out] out result and elapsed time.
 *
 * @retval 0          The job returned within the wait limit.
 * @retval -ETIMEDOUT The job did not return, or an earlier job is still stuck.
 */
int i2c_timing_run_bounded(i2c_fault_job_fn fn, void *arg, struct i2c_fault_outcome *out);

/**
 * Hand @p fn to the worker thread and return without waiting.
 *
 * Must be paired with i2c_timing_collect().  i2c_timing_run_bounded() does
 * both.
 *
 * @param[in] fn  job to run.
 * @param[in] arg passed to @p fn unchanged.
 *
 * @retval 0          The job was handed to the worker.
 * @retval -ETIMEDOUT An earlier job is still stuck.
 */
int i2c_timing_submit(i2c_fault_job_fn fn, void *arg);

/**
 * Give the job handed over by i2c_timing_submit() up to the wait limit to
 * return.
 *
 * @param[out] out result and elapsed time.
 *
 * @retval 0          The job returned within the wait limit.
 * @retval -ETIMEDOUT The job did not return, or an earlier job is still stuck.
 */
int i2c_timing_collect(struct i2c_fault_outcome *out);

/**
 * Give a stuck job one more wait limit to return.
 *
 * Called by the suite before each test while a job is stuck.  If the job
 * returns within the extra wait, its result is discarded and the worker can
 * take new jobs again.
 *
 * @retval true  No job was stuck, or the stuck job has now returned.
 * @retval false The stuck job still has not returned.
 */
bool i2c_timing_harness_recover(void);

/**
 * Report whether a job did not return within the wait limit and still has
 * not returned.
 *
 * While that holds, the worker has not returned from its call, so
 * i2c_timing_submit() refuses new jobs.  The suite waits one more wait limit
 * through i2c_timing_harness_recover() and skips the tests that follow if the
 * job still has not returned.
 *
 * @retval true  A job did not return within the wait limit and still has not.
 * @retval false No job is stuck.
 */
bool i2c_timing_harness_stuck(void);

/**
 * Run @p fn on the worker thread and report it through
 * I2C_FAULT_ASSERT_RETURNED() if it does not return within the wait limit.
 *
 * @param[in]  fn        job to run.
 * @param[in]  arg       passed to @p fn unchanged.
 * @param[in]  condition condition identifier used in the failure message.
 * @param[out] out       result and elapsed time.
 */
void i2c_timing_run_or_fail(i2c_fault_job_fn fn, void *arg, const char *condition,
			    struct i2c_fault_outcome *out);

#endif /* I2C_TIMING_H_ */
```
